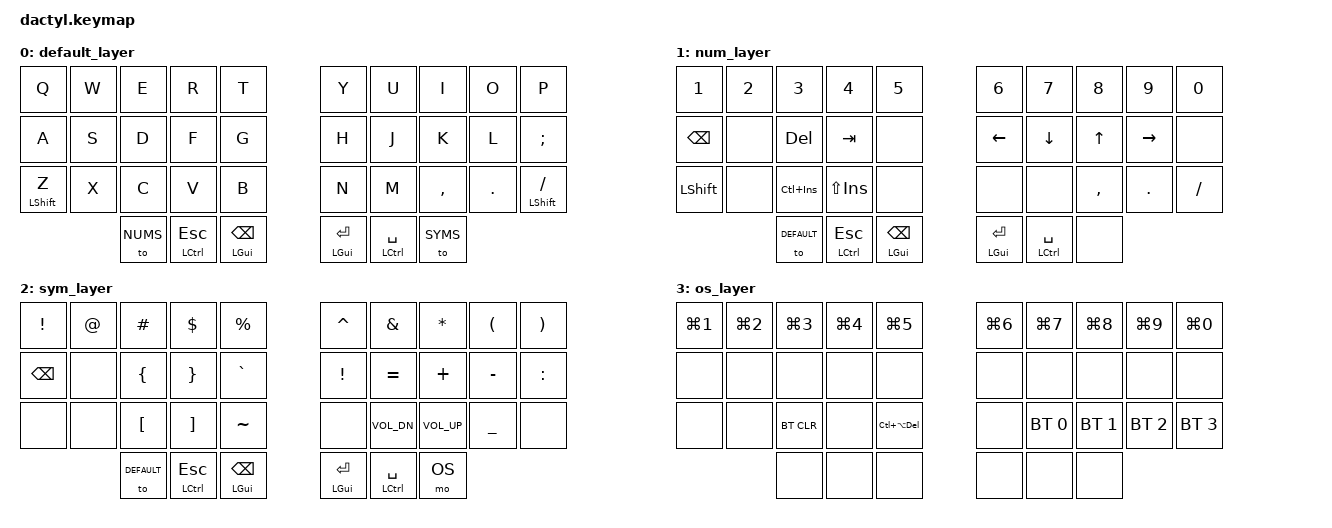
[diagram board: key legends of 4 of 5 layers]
#include <behaviors.dtsi>
#include <dt-bindings/zmk/keys.h>
#include <dt-bindings/zmk/bt.h>
#include <dt-bindings/zmk/outputs.h>

#define DEFAULT 0
#define NUMS 1
#define SYMS 2
#define OS   3
#define KEEB 4

#define HYPER(key) LS(LC(LA(LG(key))))
#define MEH(key)   LS(LC(LA(key)))

&sl {
    release-after-ms = <2000>;
};

/ {
    behaviors {        
        rht: right_hold_tap {
        compatible = "zmk,behavior-hold-tap";            
        label = "POSITIONAL_HOLD_TAP";
        #binding-cells = <2>;
        flavor = "tap-preferred";
        tapping-term-ms = <200>;// <---[[produces tap if held longer than tapping-term-ms]]            
        quick-tap-ms = <200>;            
        bindings = <&kp>, <&kp>;            
        hold-trigger-key-positions = <5 6 7 8 9>;    // <---[[right-hand keys]]"
        };

        lht: left_hold_tap {
        compatible = "zmk,behavior-hold-tap";            
        label = "POSITIONAL_HOLD_TAP";
        #binding-cells = <2>;
        flavor = "tap-preferred";
        tapping-term-ms = <200>;// <---[[produces tap if held longer than tapping-term-ms]]            
        quick-tap-ms = <200>;            
        bindings = <&kp>, <&kp>;            
        hold-trigger-key-positions = <0 1 2 3 4 5>;    // <---[[right-hand keys]]"
        };

        ht: hold_tap {
        compatible = "zmk,behavior-hold-tap";            
        label = "POSITIONAL_HOLD_TAP";
        #binding-cells = <2>;
        flavor = "tap-preferred";
        tapping-term-ms = <200>;// <---[[produces tap if held longer than tapping-term-ms]]            
        quick-tap-ms = <200>;            
        bindings = <&kp>, <&kp>;            
        };
    };

    keymap {
        compatible = "zmk,keymap";

        default_layer {
            bindings = <
            &kp Q     &kp W    &kp E     &kp R     &kp T                    &kp Y     &kp U     &kp I     &kp O     &kp P    
            &kp A     &kp S    &kp D     &kp F     &kp G                    &kp H     &kp J     &kp K     &kp L     &kp SEMI 
    &lht LSHIFT Z     &kp X    &kp C     &kp V     &kp B                    &kp N     &kp M     &kp COMMA &kp DOT   &rht LSHIFT FSLH 
                       &to NUMS  &ht LCTRL ESC   &ht LGUI BSPC                  &ht LGUI RET   &ht LCTRL SPC  &to SYMS
            >;
        };

        num_layer {
            bindings = <
    &kp N1     &kp N2  &kp N3  &kp N4   &kp N5                &kp N6     &kp N7     &kp N8   &kp N9      &kp N0 
    &kp BSPC   &none   &kp DEL   &kp TAB   &none                     &kp LEFT   &kp DOWN   &kp UP   &kp RIGHT   &none   
    &kp LSHIFT &none   &kp LC(INS)   &kp LS(INS)   &none                &none    &none   &kp COMMA   &kp DOT   &kp FSLH
             &to DEFAULT   &ht LCTRL ESC   &ht LGUI BSPC       &ht LGUI RET   &ht LCTRL SPC  &none
            >;
        };

        sym_layer {
            bindings = <
    &kp EXCL &kp AT   &kp HASH &kp DLLR &kp PRCNT             &kp CARET &kp AMPS &kp STAR  &kp LPAR    &kp RPAR    
    &kp BSPC &none   &kp LBRC   &kp RBRC   &kp GRAVE           &kp EXCL  &kp EQUAL &kp PLUS &kp MINUS   &kp COLON  
    &none    &none   &kp LBKT   &kp RBKT   &kp TILDE           &none    &kp C_VOL_DN   &kp C_VOL_UP   &kp UNDER   &none
             &to DEFAULT   &ht LCTRL ESC   &ht LGUI BSPC       &ht LGUI RET   &ht LCTRL SPC  &mo OS
            >;
        }; 

        os_layer {
            bindings = <
 &kp LG(N1) &kp LG(N2) &kp LG(N3) &kp LG(N4) &kp LG(N5)          &kp LG(N6) &kp LG(N7) &kp LG(N8) &kp LG(N9) &kp LG(N0)
       &none   &none   &none   &none   &none                            &none   &none   &none   &none   &none  
       &none   &none   &bt BT_CLR   &none   &kp LC(LA(DEL))                       &none   &bt BT_SEL 0  &bt BT_SEL 1 &bt BT_SEL 2 &bt BT_SEL 3  
                            &none   &none   &none                               &none   &none   &none   
            >;
        };
        
        keeb_layer {
            bindings = <
    &none   &none   &none   &none   &none   &none                     &none   &none   &none   &none   &none   &none   
    &none   &none   &none   &none   &none   &none                     &none   &none   &none   &none   &none   &none   
    &none   &none   &none   &none   &none   &bootloader               &reset   &none   &none   &none   &none   &none   
                            &none   &none   &none                     &none   &none   &none   
            >;
        };

    };
};
